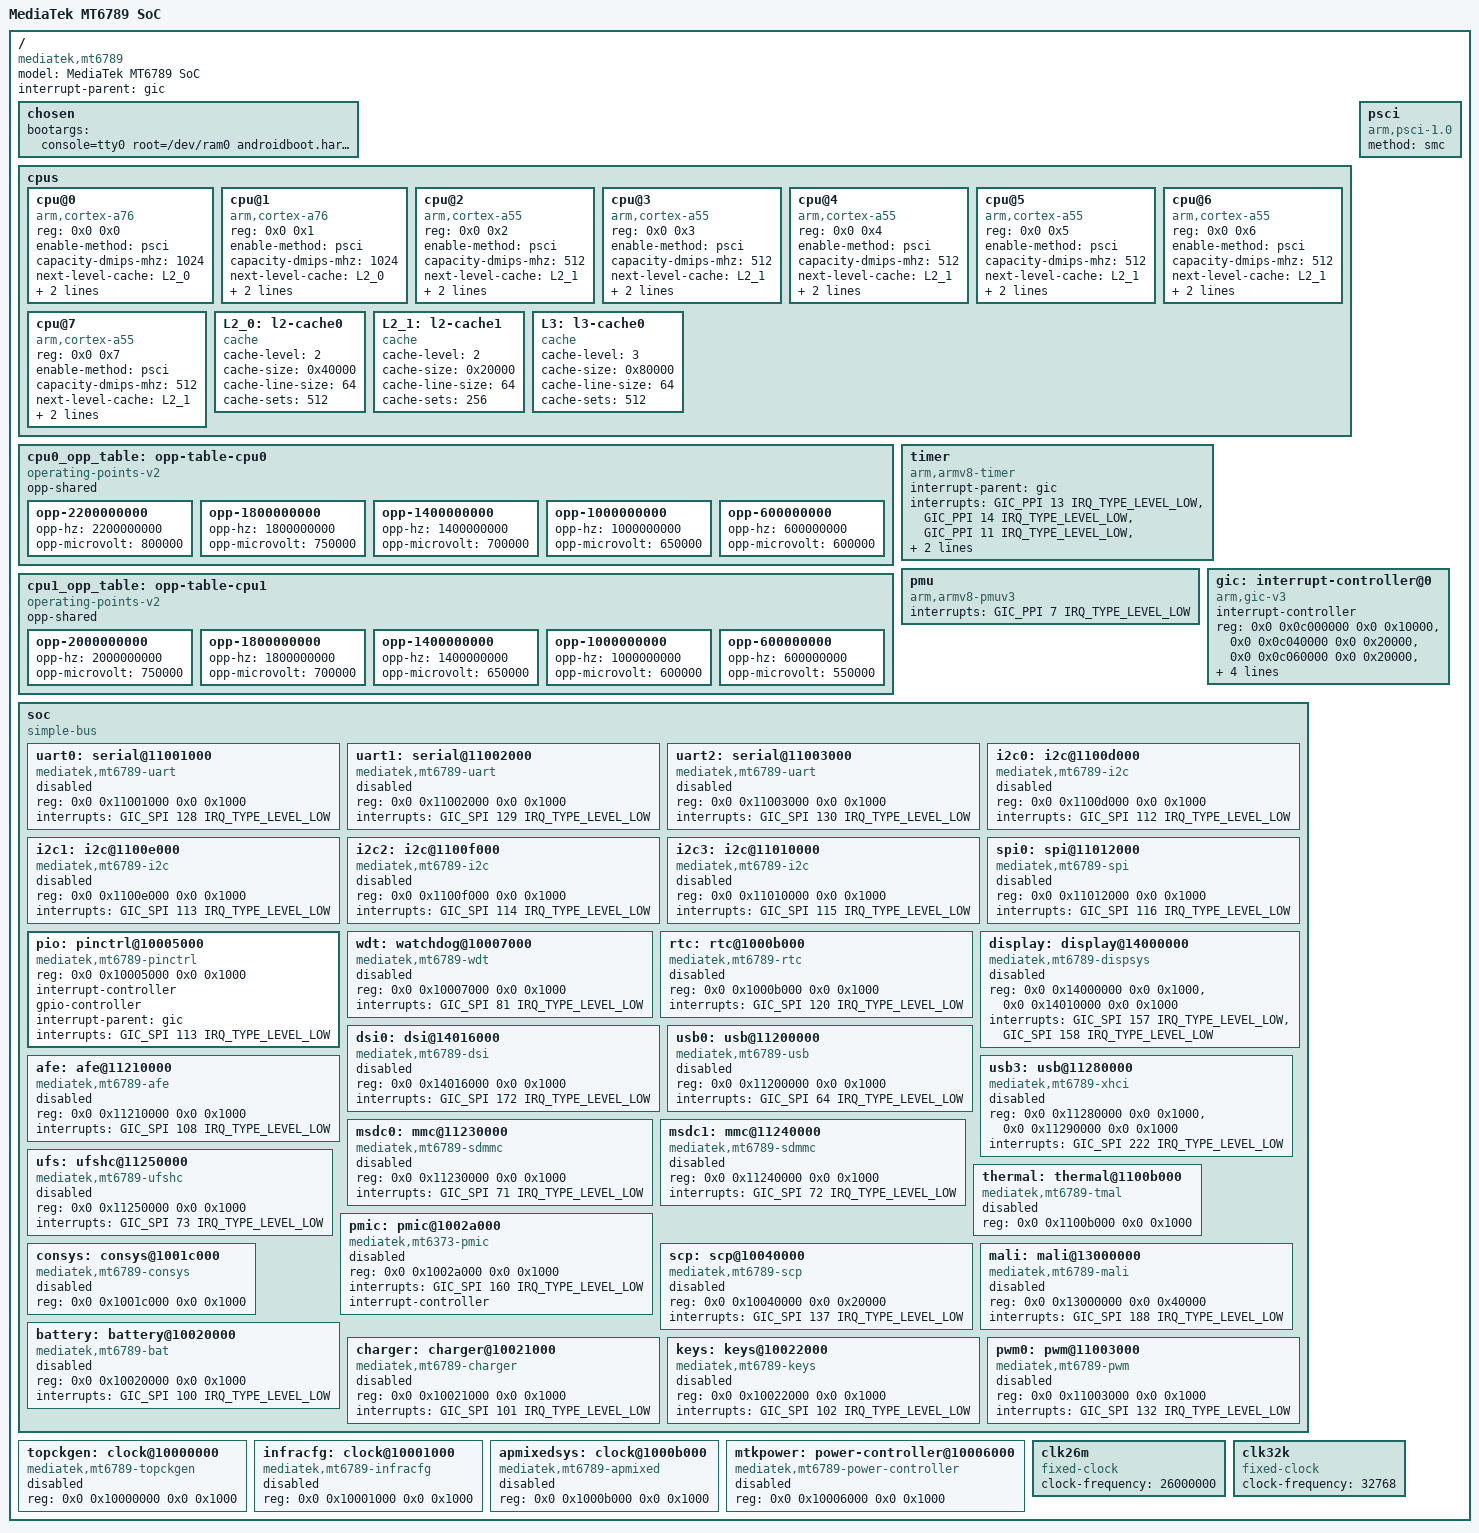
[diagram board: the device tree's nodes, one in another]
// SPDX-License-Identifier: GPL-2.0
// Device Tree Source for MediaTek MT6789 (Helio G200) - SoC Level

/dts-v1/;
#include <dt-bindings/interrupt-controller/arm-gic.h>
#include <dt-bindings/gpio.h>

/ {
    model = "MediaTek MT6789 SoC";
    compatible = "mediatek,mt6789";
    interrupt-parent = <&gic>;
    #address-cells = <2>;
    #size-cells = <2>;

    chosen {
        bootargs = "console=tty0 root=/dev/ram0 androidboot.hardware=mt6789";
    };

    cpus {
        #address-cells = <2>;
        #size-cells = <0>;

        cpu@0 {
            device_type = "cpu";
            compatible = "arm,cortex-a76";
            reg = <0x0 0x0>;
            enable-method = "psci";
            capacity-dmips-mhz = <1024>;
            next-level-cache = <&L2_0>;
            operating-points-v2 = <&cpu0_opp_table>;
            clock-frequency = <2200000000>;
        };

        cpu@1 {
            device_type = "cpu";
            compatible = "arm,cortex-a76";
            reg = <0x0 0x1>;
            enable-method = "psci";
            capacity-dmips-mhz = <1024>;
            next-level-cache = <&L2_0>;
            operating-points-v2 = <&cpu0_opp_table>;
            clock-frequency = <2200000000>;
        };

        cpu@2 {
            device_type = "cpu";
            compatible = "arm,cortex-a55";
            reg = <0x0 0x2>;
            enable-method = "psci";
            capacity-dmips-mhz = <512>;
            next-level-cache = <&L2_1>;
            operating-points-v2 = <&cpu1_opp_table>;
            clock-frequency = <2000000000>;
        };

        cpu@3 {
            device_type = "cpu";
            compatible = "arm,cortex-a55";
            reg = <0x0 0x3>;
            enable-method = "psci";
            capacity-dmips-mhz = <512>;
            next-level-cache = <&L2_1>;
            operating-points-v2 = <&cpu1_opp_table>;
            clock-frequency = <2000000000>;
        };

        cpu@4 {
            device_type = "cpu";
            compatible = "arm,cortex-a55";
            reg = <0x0 0x4>;
            enable-method = "psci";
            capacity-dmips-mhz = <512>;
            next-level-cache = <&L2_1>;
            operating-points-v2 = <&cpu1_opp_table>;
            clock-frequency = <2000000000>;
        };

        cpu@5 {
            device_type = "cpu";
            compatible = "arm,cortex-a55";
            reg = <0x0 0x5>;
            enable-method = "psci";
            capacity-dmips-mhz = <512>;
            next-level-cache = <&L2_1>;
            operating-points-v2 = <&cpu1_opp_table>;
            clock-frequency = <2000000000>;
        };

        cpu@6 {
            device_type = "cpu";
            compatible = "arm,cortex-a55";
            reg = <0x0 0x6>;
            enable-method = "psci";
            capacity-dmips-mhz = <512>;
            next-level-cache = <&L2_1>;
            operating-points-v2 = <&cpu1_opp_table>;
            clock-frequency = <2000000000>;
        };

        cpu@7 {
            device_type = "cpu";
            compatible = "arm,cortex-a55";
            reg = <0x0 0x7>;
            enable-method = "psci";
            capacity-dmips-mhz = <512>;
            next-level-cache = <&L2_1>;
            operating-points-v2 = <&cpu1_opp_table>;
            clock-frequency = <2000000000>;
        };

        L2_0: l2-cache0 {
            compatible = "cache";
            cache-level = <2>;
            cache-size = <0x40000>;
            cache-line-size = <64>;
            cache-sets = <512>;
        };

        L2_1: l2-cache1 {
            compatible = "cache";
            cache-level = <2>;
            cache-size = <0x20000>;
            cache-line-size = <64>;
            cache-sets = <256>;
        };

        L3: l3-cache0 {
            compatible = "cache";
            cache-level = <3>;
            cache-size = <0x80000>;
            cache-line-size = <64>;
            cache-sets = <512>;
        };
    };

    cpu0_opp_table: opp-table-cpu0 {
        compatible = "operating-points-v2";
        opp-shared;
        opp-2200000000 { opp-hz = <2200000000>; opp-microvolt = <800000>; };
        opp-1800000000 { opp-hz = <1800000000>; opp-microvolt = <750000>; };
        opp-1400000000 { opp-hz = <1400000000>; opp-microvolt = <700000>; };
        opp-1000000000 { opp-hz = <1000000000>; opp-microvolt = <650000>; };
        opp-600000000 { opp-hz = <600000000>; opp-microvolt = <600000>; };
    };

    cpu1_opp_table: opp-table-cpu1 {
        compatible = "operating-points-v2";
        opp-shared;
        opp-2000000000 { opp-hz = <2000000000>; opp-microvolt = <750000>; };
        opp-1800000000 { opp-hz = <1800000000>; opp-microvolt = <700000>; };
        opp-1400000000 { opp-hz = <1400000000>; opp-microvolt = <650000>; };
        opp-1000000000 { opp-hz = <1000000000>; opp-microvolt = <600000>; };
        opp-600000000 { opp-hz = <600000000>; opp-microvolt = <550000>; };
    };

    psci { compatible = "arm,psci-1.0"; method = "smc"; };

    timer {
        compatible = "arm,armv8-timer";
        interrupt-parent = <&gic>;
        interrupts = <GIC_PPI 13 IRQ_TYPE_LEVEL_LOW>, <GIC_PPI 14 IRQ_TYPE_LEVEL_LOW>,
                     <GIC_PPI 11 IRQ_TYPE_LEVEL_LOW>, <GIC_PPI 10 IRQ_TYPE_LEVEL_LOW>;
        arm,always-on;
    };

    pmu { compatible = "arm,armv8-pmuv3"; interrupts = <GIC_PPI 7 IRQ_TYPE_LEVEL_LOW>; };

    gic: interrupt-controller@0 {
        compatible = "arm,gic-v3";
        #interrupt-cells = <3>;
        interrupt-controller;
        reg = <0x0 0x0c000000 0x0 0x10000>, <0x0 0x0c040000 0x0 0x20000>,
              <0x0 0x0c060000 0x0 0x20000>, <0x0 0x0c080000 0x0 0x20000>;
        interrupts = <GIC_CPU_MASKED(0, IRQ_TYPE_LEVEL_LOW)>;
        interrupt-ranges = <0 0 255>;
    };

    soc {
        compatible = "simple-bus";
        #address-cells = <2>;
        #size-cells = <2>;
        ranges;

        uart0: serial@11001000 { compatible = "mediatek,mt6789-uart"; reg = <0x0 0x11001000 0x0 0x1000>; interrupts = <GIC_SPI 128 IRQ_TYPE_LEVEL_LOW>; status = "disabled"; };
        uart1: serial@11002000 { compatible = "mediatek,mt6789-uart"; reg = <0x0 0x11002000 0x0 0x1000>; interrupts = <GIC_SPI 129 IRQ_TYPE_LEVEL_LOW>; status = "disabled"; };
        uart2: serial@11003000 { compatible = "mediatek,mt6789-uart"; reg = <0x0 0x11003000 0x0 0x1000>; interrupts = <GIC_SPI 130 IRQ_TYPE_LEVEL_LOW>; status = "disabled"; };
        i2c0: i2c@1100d000 { compatible = "mediatek,mt6789-i2c"; reg = <0x0 0x1100d000 0x0 0x1000>; interrupts = <GIC_SPI 112 IRQ_TYPE_LEVEL_LOW>; #address-cells = <1>; #size-cells = <0>; status = "disabled"; };
        i2c1: i2c@1100e000 { compatible = "mediatek,mt6789-i2c"; reg = <0x0 0x1100e000 0x0 0x1000>; interrupts = <GIC_SPI 113 IRQ_TYPE_LEVEL_LOW>; #address-cells = <1>; #size-cells = <0>; status = "disabled"; };
        i2c2: i2c@1100f000 { compatible = "mediatek,mt6789-i2c"; reg = <0x0 0x1100f000 0x0 0x1000>; interrupts = <GIC_SPI 114 IRQ_TYPE_LEVEL_LOW>; #address-cells = <1>; #size-cells = <0>; status = "disabled"; };
        i2c3: i2c@11010000 { compatible = "mediatek,mt6789-i2c"; reg = <0x0 0x11010000 0x0 0x1000>; interrupts = <GIC_SPI 115 IRQ_TYPE_LEVEL_LOW>; #address-cells = <1>; #size-cells = <0>; status = "disabled"; };
        spi0: spi@11012000 { compatible = "mediatek,mt6789-spi"; reg = <0x0 0x11012000 0x0 0x1000>; interrupts = <GIC_SPI 116 IRQ_TYPE_LEVEL_LOW>; #address-cells = <1>; #size-cells = <0>; status = "disabled"; };
        pio: pinctrl@10005000 { compatible = "mediatek,mt6789-pinctrl"; reg = <0x0 0x10005000 0x0 0x1000>; interrupt-controller; #interrupt-cells = <2>; gpio-controller; #gpio-cells = <2>; interrupt-parent = <&gic>; interrupts = <GIC_SPI 113 IRQ_TYPE_LEVEL_LOW>; };
        wdt: watchdog@10007000 { compatible = "mediatek,mt6789-wdt"; reg = <0x0 0x10007000 0x0 0x1000>; interrupts = <GIC_SPI 81 IRQ_TYPE_LEVEL_LOW>; status = "disabled"; };
        rtc: rtc@1000b000 { compatible = "mediatek,mt6789-rtc"; reg = <0x0 0x1000b000 0x0 0x1000>; interrupts = <GIC_SPI 120 IRQ_TYPE_LEVEL_LOW>; status = "disabled"; };
        display: display@14000000 { compatible = "mediatek,mt6789-dispsys"; reg = <0x0 0x14000000 0x0 0x1000>, <0x0 0x14010000 0x0 0x1000>; interrupts = <GIC_SPI 157 IRQ_TYPE_LEVEL_LOW>, <GIC_SPI 158 IRQ_TYPE_LEVEL_LOW>; status = "disabled"; };
        dsi0: dsi@14016000 { compatible = "mediatek,mt6789-dsi"; reg = <0x0 0x14016000 0x0 0x1000>; interrupts = <GIC_SPI 172 IRQ_TYPE_LEVEL_LOW>; status = "disabled"; };
        afe: afe@11210000 { compatible = "mediatek,mt6789-afe"; reg = <0x0 0x11210000 0x0 0x1000>; interrupts = <GIC_SPI 108 IRQ_TYPE_LEVEL_LOW>; status = "disabled"; };
        usb0: usb@11200000 { compatible = "mediatek,mt6789-usb"; reg = <0x0 0x11200000 0x0 0x1000>; interrupts = <GIC_SPI 64 IRQ_TYPE_LEVEL_LOW>; status = "disabled"; };
        usb3: usb@11280000 { compatible = "mediatek,mt6789-xhci"; reg = <0x0 0x11280000 0x0 0x1000>, <0x0 0x11290000 0x0 0x1000>; interrupts = <GIC_SPI 222 IRQ_TYPE_LEVEL_LOW>; status = "disabled"; };
        msdc0: mmc@11230000 { compatible = "mediatek,mt6789-sdmmc"; reg = <0x0 0x11230000 0x0 0x1000>; interrupts = <GIC_SPI 71 IRQ_TYPE_LEVEL_LOW>; status = "disabled"; };
        msdc1: mmc@11240000 { compatible = "mediatek,mt6789-sdmmc"; reg = <0x0 0x11240000 0x0 0x1000>; interrupts = <GIC_SPI 72 IRQ_TYPE_LEVEL_LOW>; status = "disabled"; };
        ufs: ufshc@11250000 { compatible = "mediatek,mt6789-ufshc"; reg = <0x0 0x11250000 0x0 0x1000>; interrupts = <GIC_SPI 73 IRQ_TYPE_LEVEL_LOW>; status = "disabled"; };
        thermal: thermal@1100b000 { compatible = "mediatek,mt6789-tmal"; reg = <0x0 0x1100b000 0x0 0x1000>; #thermal-sensor-cells = <1>; status = "disabled"; };
        pmic: pmic@1002a000 { compatible = "mediatek,mt6373-pmic"; reg = <0x0 0x1002a000 0x0 0x1000>; interrupts = <GIC_SPI 160 IRQ_TYPE_LEVEL_LOW>; interrupt-controller; #interrupt-cells = <2>; status = "disabled"; };
        scp: scp@10040000 { compatible = "mediatek,mt6789-scp"; reg = <0x0 0x10040000 0x0 0x20000>; interrupts = <GIC_SPI 137 IRQ_TYPE_LEVEL_LOW>; status = "disabled"; };
        mali: mali@13000000 { compatible = "mediatek,mt6789-mali", "arm,mali-bifrost"; reg = <0x0 0x13000000 0x0 0x40000>; interrupts = <GIC_SPI 188 IRQ_TYPE_LEVEL_LOW>; status = "disabled"; };
        consys: consys@1001c000 { compatible = "mediatek,mt6789-consys"; reg = <0x0 0x1001c000 0x0 0x1000>; status = "disabled"; };
        battery: battery@10020000 { compatible = "mediatek,mt6789-bat"; reg = <0x0 0x10020000 0x0 0x1000>; interrupts = <GIC_SPI 100 IRQ_TYPE_LEVEL_LOW>; status = "disabled"; };
        charger: charger@10021000 { compatible = "mediatek,mt6789-charger"; reg = <0x0 0x10021000 0x0 0x1000>; interrupts = <GIC_SPI 101 IRQ_TYPE_LEVEL_LOW>; status = "disabled"; };
        keys: keys@10022000 { compatible = "mediatek,mt6789-keys"; reg = <0x0 0x10022000 0x0 0x1000>; interrupts = <GIC_SPI 102 IRQ_TYPE_LEVEL_LOW>; status = "disabled"; };
        pwm0: pwm@11003000 { compatible = "mediatek,mt6789-pwm"; reg = <0x0 0x11003000 0x0 0x1000>; interrupts = <GIC_SPI 132 IRQ_TYPE_LEVEL_LOW>; status = "disabled"; };
    };

    topckgen: clock@10000000 { compatible = "mediatek,mt6789-topckgen"; reg = <0x0 0x10000000 0x0 0x1000>; #clock-cells = <1>; status = "disabled"; };
    infracfg: clock@10001000 { compatible = "mediatek,mt6789-infracfg"; reg = <0x0 0x10001000 0x0 0x1000>; #clock-cells = <1>; status = "disabled"; };
    apmixedsys: clock@1000b000 { compatible = "mediatek,mt6789-apmixed"; reg = <0x0 0x1000b000 0x0 0x1000>; #clock-cells = <1>; status = "disabled"; };
    mtkpower: power-controller@10006000 { compatible = "mediatek,mt6789-power-controller"; reg = <0x0 0x10006000 0x0 0x1000>; #power-domain-cells = <1>; status = "disabled"; };

    clk26m: clk26m { compatible = "fixed-clock"; #clock-cells = <0>; clock-frequency = <26000000>; };
    clk32k: clk32k { compatible = "fixed-clock"; #clock-cells = <0>; clock-frequency = <32768>; };
};
